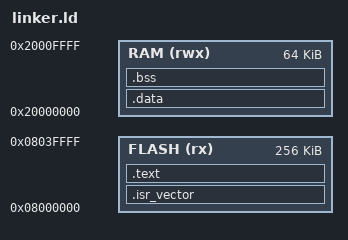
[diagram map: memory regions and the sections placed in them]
MEMORY
{
  FLASH (rx) : ORIGIN = 0x08000000, LENGTH = 256K
  RAM (rwx)  : ORIGIN = 0x20000000, LENGTH = 64K
}

SECTIONS
{
  .isr_vector : {
    KEEP(*(.isr_vector))
  } > FLASH

  .text : {
    *(.text*)
    *(.rodata*)
  } > FLASH

  .data : AT (ADDR(.text) + SIZEOF(.text)) {
    _sdata = .;
    *(.data*)
    _edata = .;
  } > RAM

  _etext = LOADADDR(.data);

  .bss : {
    _sbss = .;
    *(.bss*)
    *(COMMON)
    _ebss = .;
  } > RAM
}
